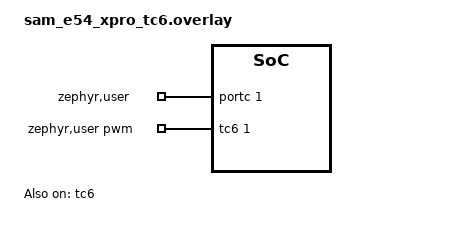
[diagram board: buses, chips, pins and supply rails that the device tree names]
/*
 * Copyright (c) 2025 Microchip Technology Inc.
 *
 * SPDX-License-Identifier: Apache-2.0
 */

/* connect the PB17 to PC01 */

#include <zephyr/dt-bindings/gpio/gpio.h>

/ {
	zephyr,user {
		pwms = <&tc6 1 PWM_MSEC(1) 0>;
		gpios = <&portc 1 GPIO_ACTIVE_HIGH>;
	};
};

&tc6 {
	status = "okay";
	compatible = "microchip,tc-g1-pwm";
	#pwm-cells = <3>;
	pinctrl-0 = <&tc6_pwm_default>;
	pinctrl-names = "default";
	prescaler = <4>;
};

&pinctrl {
	tc6_pwm_default: tc6_pwm_default {
		group1 {
			pinmux = <PB17E_TC6_WO1>;
		};
	};
};
